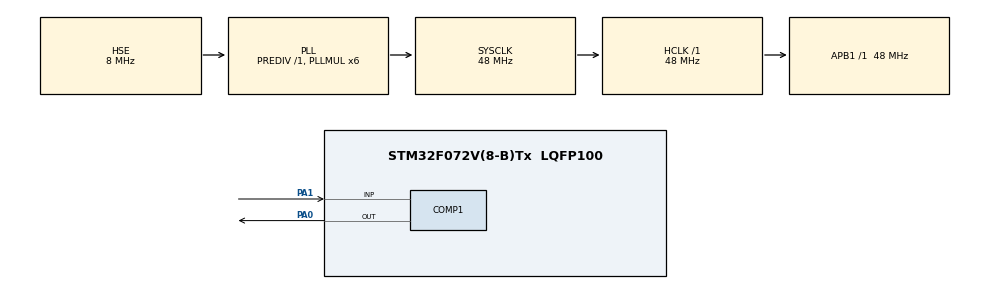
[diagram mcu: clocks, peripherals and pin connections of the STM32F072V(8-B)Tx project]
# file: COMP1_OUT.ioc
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Mcu.Family=STM32F0
Mcu.Name=STM32F072V(8-B)Tx
Mcu.Package=LQFP100
PA0.Mode=ExternalOutput
PA0.Signal=COMP1_OUT
PA1.Mode=INP
PA1.Signal=COMP1_INP
PF0-OSC_IN.Mode=HSE-External-Oscillator
PF0-OSC_IN.Signal=RCC_OSC_IN
PF1-OSC_OUT.Mode=HSE-External-Oscillator
PF1-OSC_OUT.Signal=RCC_OSC_OUT
ProjectManager.HeapSize=0x200
ProjectManager.StackSize=0x400
ProjectManager.TargetToolchain=MDK-ARM V5
RCC.AHBFreq_Value=48000000
RCC.APB1Freq_Value=48000000
RCC.APB1TimFreq_Value=48000000
RCC.HCLKFreq_Value=48000000
RCC.HSIState=RCC_HSI_ON
RCC.PLLMUL=RCC_PLL_MUL6
RCC.PLLSourceVirtual=RCC_PLLSOURCE_HSE
RCC.SYSCLKFreq_VALUE=48000000
RCC.SYSCLKSource=RCC_SYSCLKSOURCE_PLLCLK
VP_COMP1_VS_VREFINT.Mode=VREFINT
board=COMP1_OUT

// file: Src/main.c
/**
  ******************************************************************************
  * File Name          : main.c
  * Description        : Main program body
	******************************************************************************
  *
  * COPYRIGHT(c) 2017 STMicroelectronics
  *
  * Redistribution and use in source and binary forms, with or without modification,
  * are permitted provided that the following conditions are met:
  *   1. Redistributions of source code must retain the above copyright notice,
  *      this list of conditions and the following disclaimer.
  *   2. Redistributions in binary form must reproduce the above copyright notice,
  *      this list of conditions and the following disclaimer in the documentation
  *      and/or other materials provided with the distribution.
  *   3. Neither the name of STMicroelectronics nor the names of its contributors
  *      may be used to endorse or promote products derived from this software
  *      without specific prior written permission.
  *
  * THIS SOFTWARE IS PROVIDED BY THE COPYRIGHT HOLDERS AND CONTRIBUTORS "AS IS"
  * AND ANY EXPRESS OR IMPLIED WARRANTIES, INCLUDING, BUT NOT LIMITED TO, THE
  * IMPLIED WARRANTIES OF MERCHANTABILITY AND FITNESS FOR A PARTICULAR PURPOSE ARE
  * DISCLAIMED. IN NO EVENT SHALL THE COPYRIGHT HOLDER OR CONTRIBUTORS BE LIABLE
  * FOR ANY DIRECT, INDIRECT, INCIDENTAL, SPECIAL, EXEMPLARY, OR CONSEQUENTIAL
  * DAMAGES (INCLUDING, BUT NOT LIMITED TO, PROCUREMENT OF SUBSTITUTE GOODS OR
  * SERVICES; LOSS OF USE, DATA, OR PROFITS; OR BUSINESS INTERRUPTION) HOWEVER
  * CAUSED AND ON ANY THEORY OF LIABILITY, WHETHER IN CONTRACT, STRICT LIABILITY,
  * OR TORT (INCLUDING NEGLIGENCE OR OTHERWISE) ARISING IN ANY WAY OUT OF THE USE
  * OF THIS SOFTWARE, EVEN IF ADVISED OF THE POSSIBILITY OF SUCH DAMAGE.
  *
  ******************************************************************************
  */
#include "stm32f0xx_hal.h"

COMP_HandleTypeDef hcomp1;

/* USER CODE BEGIN PV */
/* Private variables ---------------------------------------------------------*/

/* USER CODE END PV */

void SystemClock_Config(void);
void Error_Handler(void);
static void MX_GPIO_Init(void);
static void MX_COMP1_Init(void);

/* USER CODE BEGIN PFP */
/* Private function prototypes -----------------------------------------------*/

/* USER CODE END PFP */

/* USER CODE BEGIN 0 */
uint32_t  status;    /* 定义状态变量 */

/* USER CODE END 0 */

int main(void)
{

  /* MCU Configuration----------------------------------------------------------*/

  /* Reset of all peripherals, Initializes the Flash interface and the Systick. */
  HAL_Init();

  /* Configure the system clock */
  SystemClock_Config();

  /* Initialize all configured peripherals */
  MX_GPIO_Init();
  MX_COMP1_Init();

  /* USER CODE BEGIN 2 */

	/* 使能模拟比较器1 */
	status = HAL_COMP_Start (&hcomp1);

  /* USER CODE END 2 */

  /* Infinite loop */
  while (1)
  {

  }

}

/** System Clock Configuration
*/
void SystemClock_Config(void)
{

  RCC_OscInitTypeDef RCC_OscInitStruct;
  RCC_ClkInitTypeDef RCC_ClkInitStruct;

  RCC_OscInitStruct.OscillatorType = RCC_OSCILLATORTYPE_HSE;
  RCC_OscInitStruct.HSEState = RCC_HSE_ON;
  RCC_OscInitStruct.PLL.PLLState = RCC_PLL_ON;
  RCC_OscInitStruct.PLL.PLLSource = RCC_PLLSOURCE_HSE;
  RCC_OscInitStruct.PLL.PLLMUL = RCC_PLL_MUL6;
  RCC_OscInitStruct.PLL.PREDIV = RCC_PREDIV_DIV1;
  if (HAL_RCC_OscConfig(&RCC_OscInitStruct) != HAL_OK)
  {
    Error_Handler();
  }

  RCC_ClkInitStruct.ClockType = RCC_CLOCKTYPE_HCLK|RCC_CLOCKTYPE_SYSCLK
                              |RCC_CLOCKTYPE_PCLK1;
  RCC_ClkInitStruct.SYSCLKSource = RCC_SYSCLKSOURCE_PLLCLK;
  RCC_ClkInitStruct.AHBCLKDivider = RCC_SYSCLK_DIV1;
  RCC_ClkInitStruct.APB1CLKDivider = RCC_HCLK_DIV1;
  if (HAL_RCC_ClockConfig(&RCC_ClkInitStruct, FLASH_LATENCY_1) != HAL_OK)
  {
    Error_Handler();
  }

  HAL_SYSTICK_Config(HAL_RCC_GetHCLKFreq()/1000);

  HAL_SYSTICK_CLKSourceConfig(SYSTICK_CLKSOURCE_HCLK);

  /* SysTick_IRQn interrupt configuration */
  HAL_NVIC_SetPriority(SysTick_IRQn, 0, 0);
}

/* COMP1 init function */
static void MX_COMP1_Init(void)
{

  hcomp1.Instance = COMP1;
  hcomp1.Init.InvertingInput = COMP_INVERTINGINPUT_VREFINT;
  hcomp1.Init.NonInvertingInput = COMP_NONINVERTINGINPUT_IO1;
  hcomp1.Init.Output = COMP_OUTPUT_NONE;
  hcomp1.Init.OutputPol = COMP_OUTPUTPOL_NONINVERTED;
  hcomp1.Init.Hysteresis = COMP_HYSTERESIS_NONE;
  hcomp1.Init.Mode = COMP_MODE_HIGHSPEED;
  hcomp1.Init.WindowMode = COMP_WINDOWMODE_DISABLE;
  hcomp1.Init.TriggerMode = COMP_TRIGGERMODE_NONE;
  if (HAL_COMP_Init(&hcomp1) != HAL_OK)
  {
    Error_Handler();
  }

}

/** Configure pins as
        * Analog
        * Input
        * Output
        * EVENT_OUT
        * EXTI
*/
static void MX_GPIO_Init(void)
{

  /* GPIO Ports Clock Enable */
  __HAL_RCC_GPIOF_CLK_ENABLE();
  __HAL_RCC_GPIOA_CLK_ENABLE();

}

void Error_Handler(void)
{
  while(1)
  {
  }
}

/************************ (C) COPYRIGHT STMicroelectronics *****END OF FILE****/
